# I2C0_1.0 register map
Vendor: Texas Instruments
Registers are 32-bit, read-write, no defined reset value unless marked. A register's access mark holds for its fields unless they carry their own. Offsets are as the file gives them; [hi:lo] are bit positions; lines under a group give offsets from that group; {n}, {i} and the like mark numbered series; 'fields as' and 'values as' point back to an identical list.

## I2C0 (part 2 of 2)
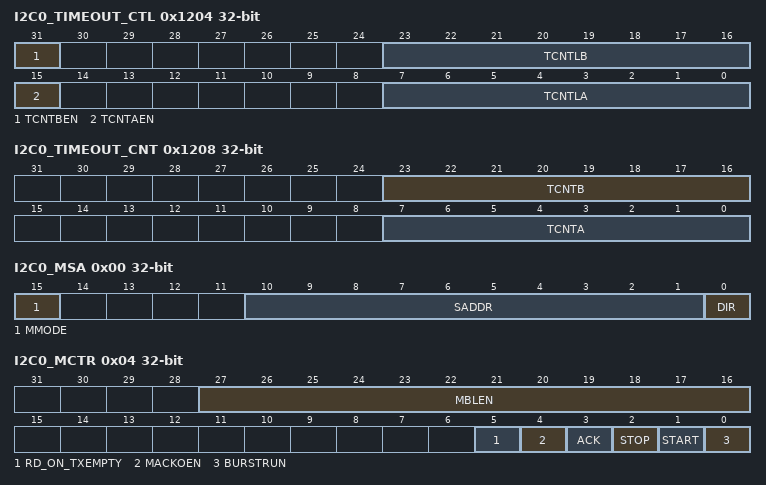
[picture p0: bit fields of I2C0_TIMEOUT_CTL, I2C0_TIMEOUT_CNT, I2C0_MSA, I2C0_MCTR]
0x1204 I2C0_TIMEOUT_CTL — I2C Timeout Count Control Register
  [31] TCNTBEN — Timeout Counter B Enable
    0=DISABLE (Disable Timeout Counter B); 1=ENABLE (Enable Timeout Counter B)
  [23:16] TCNTLB — Timeout Count B Load: Counter B is used for SCL High Detection. This field contains the upper 8 bits of a 12-bit pre-load value for the Timeout B count. NOTE: The value of CNTLB must be greater than 1h. Each count is equal to 1* clock period. For example, with 10MHz functional clock one timeout period will be equal to1*100ns.
    0=MINIMUM (Smallest possible value); 255=MAXIMUM (Highest possible value)
  [15] TCNTAEN — Timeout Counter A Enable
    values as TCNTBEN
  [7:0] TCNTLA — Timeout counter A load value Counter A is used for SCL low detection. This field contains the upper 8 bits of a 12-bit pre-load value for the Timeout A count. NOTE: The value of CNTLA must be greater than 1h. Each count is equal to 520 times the timeout period of functional clock. For example, with 8MHz functional clock and a 100KHz operating I2C clock, one timeout period will be equal to (1 / 8MHz) * 520 or 65 us.
    0=MINIMUM (Smallest Value); 255=MAXIMUM (Highest possible value)
0x1208 I2C0_TIMEOUT_CNT access per field — I2C Timeout Count Register
  [23:16] TCNTB rw — Timeout Count B Current Count: This field contains the upper 8 bits of a 12-bit current counter for timeout counter B
    values as I2C0_TIMEOUT_CTL.TCNTLA
  [7:0] TCNTA ro — Timeout Count A Current Count: This field contains the upper 8 bits of a 12-bit current counter for timeout counter A
    values as I2C0_TIMEOUT_CTL.TCNTLA
0x1210 I2C0_MASTER group
  0x00 I2C0_MSA — I2C Master Slave Address Register
    [15] MMODE — This bit selects the adressing mode to be used in master mode When 0, 7-bit addressing is used. When 1, 10-bit addressing is used.
      0=MODE7 (7-bit addressing mode); 1=MODE10 (10-bit addressing mode)
    [10:1] SADDR — I2C Slave Address This field specifies bits A9 through A0 of the slave address. In 7-bit addressing mode as selected by MSA.MODE bit, the top 3 bits are don't care
      0=MINIMUM (Smallest value); 0x3FF=MAXIMUM (Highest possible value)
    [0] DIR — Receive/Send The DIR bit specifies if the next master operation is a Receive (High) or Transmit (Low). 0h = Transmit 1h = Receive
      0=TRANSMIT (The master is in transmit mode.); 1=RECEIVE (The master is in receive mode.)
  0x04 I2C0_MCTR — I2C Master Control Register
    [27:16] MBLEN — I2C transaction length This field contains the programmed length of bytes of the Transaction.
      0=MINIMUM (Smallest value); 0xFFF=MAXIMUM (Highest possible value)
    [5] RD_ON_TXEMPTY — Read on TX Empty
      0=DISABLE (No special behavior); 1=ENABLE (When 1 the master will transmit all bytes from the TX FIFO before continuing with the programmed Burst Run Read. If the DIR is not set to Read in the MSA then this bit is ignored. The Start must be set in the MCTR for proper I2C protocol. The master will first send the Start Condition, I2C Address with R/W bit set to write, before sending the bytes in the TX FIFO. When the TX FIFO is empty, the I2C transaction will continue as programmed in MTCR and MSA without sending a Stop Condition. This is intended to be used to perform simple I2C command based reads transition that will complete after initiating them without having to get an interrupt to turn the bus around.)
    [4] MACKOEN — Master ACK overrride Enable
      0=DISABLE (No special behavior); 1=ENABLE (When 1 and the master is receiving data and the number of bytes indicated in MBLEN have been received, the state machine will generate an rxdone interrupt and wait at the start of the ACK for FW to indicate if an ACK or NACK should be sent. The ACK or NACK is selected by writing the MCTR register and setting ACK accordingly. The other fields in this register can also be written at this time to continue on with the transaction. If a NACK is sent the state machine will automatically send a Stop.)
    [3] ACK — Data Acknowledge Enable. Software needs to configure this bit to send the ACK or NACK. See field decoding in Table: MCTR Field decoding.
      0=DISABLE (The last received data byte of a transaction is not acknowledged automatically by the master.); 1=ENABLE (The last received data byte of a transaction is acknowledged automatically by the master.)
    [2] STOP — Generate STOP
      0=DISABLE (The controller does not generate the STOP condition.); 1=ENABLE (The controller generates the STOP condition. See field decoding in Table: MCTR Field decoding.)
    [1] START — Generate START
      0=DISABLE (The controller does not generate the START condition.); 1=ENABLE (The controller generates the START or repeated START condition. See field decoding in Table: MCTR Field decoding.)
    [0] BURSTRUN — I2C Master Enable and start transaction
      0=DISABLE (In standard mode, this encoding means the master is unable to transmit or receive data.); 1=ENABLE (The master is able to transmit or receive data. See field decoding in Table: MCTR Field decoding.)
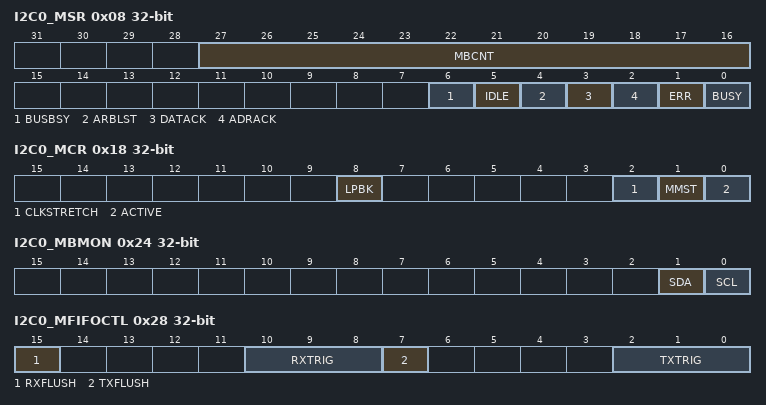
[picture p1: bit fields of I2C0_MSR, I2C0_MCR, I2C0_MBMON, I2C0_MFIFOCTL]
  0x08 I2C0_MSR ro — I2C Master Status Register
    [27:16] MBCNT — I2C Master Transaction Count This field contains the current count-down value of the transaction.
      values as I2C0_MASTER.I2C0_MCTR.MBLEN
    [6] BUSBSY — I2C Bus is Busy Master State Machine will wait until this bit is cleared before starting a transaction. When first enabling the Master in multi master environments, FW should wait for one I2C clock period after setting ACTIVE high before writing to the MTCR register to start the transaction so that if SCL goes low it will trigger the BUSBSY.
      0=CLEARED (The I2C bus is idle.); 1=SET ('This Status bit is set on a START or when SCL goes low. It is cleared on a STOP, or when a SCL high bus busy timeout occurs and SCL and SDA are both high. This status is cleared when the ACTIVE bit is low. Note that the Master State Machine will wait until this bit is cleared before starting an I2C transaction. When first enabling the Master in multi master environments, FW should wait for one I2C clock period after setting ACTIVE high before writing to the MTCR register to start the transaction so that if SCL goes low it will trigger the BUSBSY.)
    [5] IDLE — I2C Idle
      0=CLEARED (The I2C controller is not idle.); 1=SET (The I2C controller is idle.)
    [4] ARBLST — Arbitration Lost
      0=CLEARED (The I2C controller won arbitration.); 1=SET (The I2C controller lost arbitration.)
    [3] DATACK — Acknowledge Data
      0=CLEARED (The transmitted data was acknowledged); 1=SET (The transmitted data was not acknowledged.)
    [2] ADRACK — Acknowledge Address
      0=CLEARED (The transmitted address was acknowledged); 1=SET (The transmitted address was not acknowledged.)
    [1] ERR — Error The error can be from the slave address not being acknowledged or the transmit data not being acknowledged.
      0=CLEARED (No error was detected on the last operation.); 1=SET (An error occurred on the last operation.)
    [0] BUSY — I2C Master FSM Busy The BUSY bit is set during an ongoing transaction, so is set during the transmit/receive of the amount of data set in MBLEN including START, RESTART, Address and STOP signal generation when required for the current transaction.
      0=CLEARED (The controller is idle.); 1=SET (The controller is busy.)
  0x0C I2C0_MRXDATA ro — I2C Master RXData
    [7:0] VALUE — Received Data. This field contains the last received data.
      0=MINIMUM (Smallest value); 255=MAXIMUM (Highest possible value)
  0x10 I2C0_MTXDATA — I2C Master TXData
    [7:0] VALUE — Transmit Data This byte contains the data to be transferred during the next transaction.
      values as I2C0_MASTER.I2C0_MRXDATA.VALUE
  0x14 I2C0_MTPR — I2C Master Timer Period
    [6:0] TPR — Timer Period This field is used in the equation to configure SCL_PERIOD : SCL_PERIOD = (1 + TPR ) * (SCL_LP + SCL_HP ) * INT_CLK_PRD where: SCL_PRD is the SCL line period (I2C clock). TPR is the Timer Period register value (range of 1 to 127). SCL_LP is the SCL Low period (fixed at 6). SCL_HP is the SCL High period (fixed at 4). CLK_PRD is the functional clock period in ns.
      0=MINIMUM (Smallest value); 127=MAXIMUM (Highest possible value)
  0x18 I2C0_MCR — I2C Master Configuration
    [8] LPBK — I2C Loopback
      0=DISABLE (Normal operation.); 1=ENABLE (The controller in a test mode loopback configuration.)
    [2] CLKSTRETCH — Clock Stretching. This bit controls the support for clock stretching of the I2C bus.
      0=DISABLE (Disables the clock stretching detection. This can be disabled if no slave on the bus does support clock streching, so that the maximum speed on the bus can be reached.); 1=ENABLE (Enables the clock stretching detection. Enabling the clock strechting ensures compliance to the I2C standard but could limit the speed due the clock stretching.)
    [1] MMST — Multimaster mode. In Multimaster mode the SCL high time counts once the SCL line has been detected high. If this is not enabled the high time counts as soon as the SCL line has been set high by the I2C controller.
      0=DISABLE (Disable Multimaster mode.); 1=ENABLE (Enable Multimaster mode.)
    [0] ACTIVE — Device Active After this bit has been set, it should not be set again unless it has been cleared by writing a 0 or by a reset, otherwise transfer failures may occur.
      0=DISABLE (Disables the I2C master operation.); 1=ENABLE (Enables the I2C master operation.)
  0x24 I2C0_MBMON ro — I2C Master Bus Monitor
    [1] SDA — I2C SDA Status
      0=CLEARED (The I2CSDA signal is low.); 1=SET (The I2CSDA signal is high. Note: During and right after reset, the SDA pin is in GPIO input mode without the internal pull enabled. For proper I2C operation, the user should have the external pull-up resistor in place before starting any I2C operations.)
    [0] SCL — I2C SCL Status
      0=CLEARED (The I2CSCL signal is low.); 1=SET (The I2CSCL signal is high. Note: During and right after reset, the SCL pin is in GPIO input mode without the internal pull enabled. For proper I2C operation, the user should have the external pull-up resistor in place before starting any I2C operations.)
  0x28 I2C0_MFIFOCTL — I2C Master FIFO Control
    [15] RXFLUSH — RX FIFO Flush Setting this bit will Flush the RX FIFO. Before reseting this bit to stop Flush the RXFIFOCNT should be checked to be 0 and indicating that the Flush has completed.
      0=NOFLUSH (Do not Flush FIFO); 1=FLUSH (Flush FIFO)
    [10:8] RXTRIG — RX FIFO Trigger Indicates at what fill level in the RX FIFO a trigger will be generated. Note: Programming RXTRIG to 0x0 has no effect since no data is present to transfer out of RX FIFO.
      {v}=LEVEL_{v+1} (Trigger when RX FIFO contains >= {v+1} byte) (v=4..7)
    [7] TXFLUSH — TX FIFO Flush Setting this bit will Flush the TX FIFO. Before reseting this bit to stop Flush the TXFIFOCNT should be checked to be 8 and indicating that the Flush has completed.
      0=NOFLUSH (Do not Flush FIFO); 1=FLUSH (Flush FIFO)
    [2:0] TXTRIG — TX FIFO Trigger Indicates at what fill level in the TX FIFO a trigger will be generated.
      {v}=LEVEL_{v} (Trigger when TX FIFO contains {v} byte) (v=4..7)
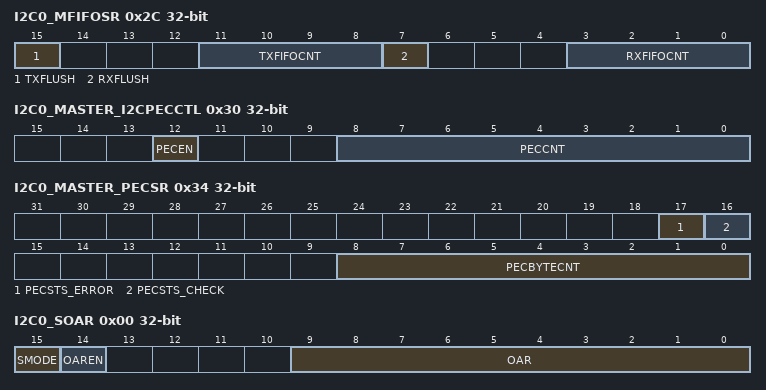
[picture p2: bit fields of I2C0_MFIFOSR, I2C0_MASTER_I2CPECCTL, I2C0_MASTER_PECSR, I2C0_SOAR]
  0x2C I2C0_MFIFOSR access per field — I2C Master FIFO Status Register
    [15] TXFLUSH rw — TX FIFO Flush When this bit is set a Flush operation for the TX FIFO is active. Clear the TXFLUSH bit in the control register to stop.
      0=INACTIVE (FIFO Flush not active); 1=ACTIVE (FIFO Flush active)
    [11:8] TXFIFOCNT ro — Number of Bytes which could be put into the TX FIFO
      0=MINIMUM (Smallest value); 8=MAXIMUM (Highest possible value)
    [7] RXFLUSH rw — RX FIFO Flush When this bit is set a Flush operation for the RX FIFO is active. Clear the RXFLUSH bit in the control register to stop.
      values as TXFLUSH
    [3:0] RXFIFOCNT ro — Number of Bytes which could be read from the RX FIFO
      values as TXFIFOCNT
  0x30 I2C0_MASTER_I2CPECCTL — I2C master PEC control register
    [12] PECEN — PEC Enable This bit enables the SMB Packet Error Checking (PEC). When enabled the PEC is calculated on all bits accept the Start, Stop, Ack and Nack. The PEC LSFR and the Byte Counter is set to 0 when the State Machine is in the IDLE state, which occur following a Stop or when a timeout occurs. The Counter is also set to 0 after the PEC byte is sent or received. Note that the NACK is automatically send following a PEC byte that results in a PEC error. The PEC Polynomial is x^8 + x^2 + x^1 + 1.
      0=DISABLE (PEC is disabled in master mode); 1=ENABLE (PEC is enabled in master mode)
    [8:0] PECCNT — PEC Count When this field is non zero, the number of I2C bytes are counted (Note that although the PEC is calculated on the I2C address it is not counted at a byte). When the byte count = PECCNT and the state machine is transmitting, the contents of the LSFR is loaded into the shift register instead of the byte received from the Tx FIFO. When the state machine is receiving, after the last bit of this byte is received the LSFR is checked and if it is non-zero, a PEC RX Error interrupt is generated. The I2C packet must be padded to include the PEC byte for both transmit and receive. In transmit mode the FIFO must be loaded with a dummy PEC byte. In receive mode the PEC byte will be passed to the Rx FIFO. In the normal Master use case, FW would set PECEN=1 and PECCNT=SMB packet length (Not including Slave Address byte, but including the PEC byte). FW would then configure DMA to allow the packet to complete unassisted and write MCTR to initiate the transaction. Note that when the byte count = PEC CNT, the byte count is reset to 0 and multiple PEC calculation can automatically occur within a single I2C transaction. Note that any write to the MASTER_I2CPECCTL Register will clear the current PEC Byte Count in the Master State Machine.
      0=MINIMUM (Minimum Value); 0x1FF=MAXIMUM (Maximum Value)
  0x34 I2C0_MASTER_PECSR — I2C master PEC status register
    [17] PECSTS_ERROR — This status bit indicates if a PEC check error occurred in the transaction that occurred before the last Stop. Latched on Stop.
      0=CLEARED (Indicates PEC check error did not occurr in the transaction that occurred before the last Stop); 1=SET (Indicates if a PEC check error occurred in the transaction that occurred before the last Stop)
    [16] PECSTS_CHECK — This status bit indicates if the PEC was checked in the transaction that occurred before the last Stop. Latched on Stop.
      0=CLEARED (Indicates PEC was not checked in the transaction that occurred before the last Stop); 1=SET (Indicates if the PEC was checked in the transaction that occurred before the last Stop)
    [8:0] PECBYTECNT — PEC Byte Count This is the current PEC Byte Count of the Master State Machine.
      0=MINIMUM (Minimum Value); 0x1FF=MAXIMUM (Maximum Value)
0x1250 I2C0_SLAVE group
  0x00 I2C0_SOAR — I2C Slave Own Address
    [15] SMODE — This bit selects the adressing mode to be used in slave mode. When 0, 7-bit addressing is used. When 1, 10-bit addressing is used.
      0=MODE7 (Enable 7-bit addressing); 1=MODE10 (Enable 10-bit addressing)
    [14] OAREN — I2C Slave Own Address Enable
      0=DISABLE (Disable OAR address); 1=ENABLE (Enable OAR address)
    [9:0] OAR — I2C Slave Own Address: This field specifies bits A9 through A0 of the slave address. In 7-bit addressing mode as selected by I2CSOAR.MODE bit, the top 3 bits are don't care
      values as I2C0_MASTER.I2C0_MSA.SADDR
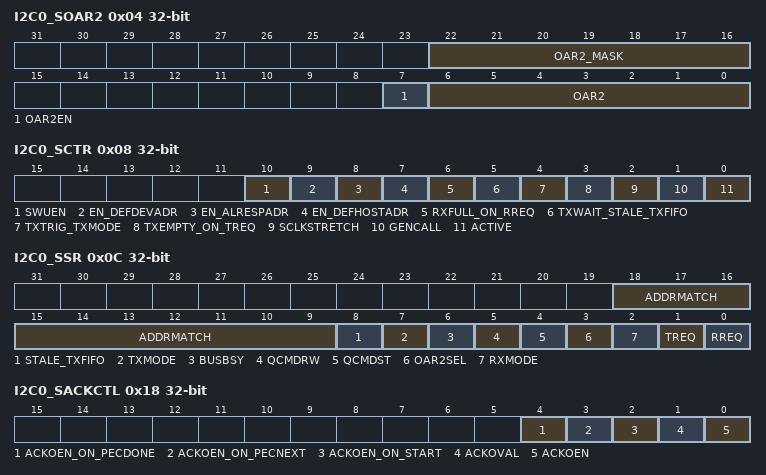
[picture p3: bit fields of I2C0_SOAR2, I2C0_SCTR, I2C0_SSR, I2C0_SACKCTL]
  0x04 I2C0_SOAR2 — I2C Slave Own Address 2
    [22:16] OAR2_MASK — I2C Slave Own Address 2 Mask: This field specifies bits A6 through A0 of the slave address. The bits with value 1 in SOAR2.OAR2_MASK field will make the corresponding incoming address bits to match by default regardless of the value inside SOAR2.OAR2 i.e. corresponding SOAR2.OAR2 bit is a dont care.
      0=MINIMUM (Minimum Value); 127=MAXIMUM (Maximum Value)
    [7] OAR2EN — I2C Slave Own Address 2 Enable
      0=DISABLE (The alternate address is disabled.); 1=ENABLE (Enables the use of the alternate address in the OAR2 field.)
    [6:0] OAR2 — I2C Slave Own Address 2 This field specifies the alternate OAR2 address.
      values as I2C0_MASTER.I2C0_MTPR.TPR
  0x08 I2C0_SCTR — I2C Slave Control Register
    [10] SWUEN — Slave Wakeup Enable
      0=DISABLE (When 0, the slave is not allowed to clock stretch on START detection); 1=ENABLE (When 1, the slave is allowed to clock stretch on START detection and wait for faster clock to be abvailable. This allows clean wake up support for I2C in low power mode use cases)
    [9] EN_DEFDEVADR — Enable Deault device address
      0=DISABLE (When this bit is 0, the default device address is not matched. NOTE: it may still be matched if programmed inside SOAR/SOAR2.); 1=ENABLE (When this bit is 1, default device address of 7h110_0001 is always matched by the slave address match logic.)
    [8] EN_ALRESPADR — Enable Alert Response Address
      0=DISABLE (When this bit is 0, the alert response address is not matched. NOTE: it may still be matched if programmed inside SOAR/SOAR2); 1=ENABLE (When this bit is 1, alert response address of 7h000_1100 is always matched by the slave address match logic.)
    [7] EN_DEFHOSTADR — Enable Default Host Address
      0=DISABLE (When this bit is 0, the default host address is not matched NOTE: it may still be matched if programmed inside SOAR/SOAR2); 1=ENABLE (When this bit is 1, default host address of 7h000_1000 is always matched by the slave address match logic.)
    [6] RXFULL_ON_RREQ — Rx full interrupt generated on RREQ condition as indicated in SSR
      0=DISABLE (When 0, RIS:SRXFULL will be set when only the Slave RX FIFO is full. This allows the SRXFULL interrupt to be used to indicate that the I2C bus is being clock stretched and that the FW must either read the RX FIFO or ACK/NACK the current Rx byte.); 1=ENABLE (When 1, RIS:SRXFULL will be set when the Slave State Machine is in the RX_WAIT or RX_ACK_WAIT states which occurs when the I2C transaction is clock stretched because the RX FIFO is full or the ACKOEN has been set and the state machine is waiting for FW to ACK/NACK the current byte.)
    [5] TXWAIT_STALE_TXFIFO — Tx transfer waits when stale data in Tx FIFO. This prevents stale bytes left in the TX FIFO from automatically being sent on the next I2C packet. Note: this should be used with TXEMPTY_ON_TREQ set to prevent the Slave State Machine from waiting for TX FIFO data without an interrupt notification when the FIFO data is stale.
      0=DISABLE (When 0, the TX FIFO empty signal to the Slave State Machine indicates that the TX FIFO is empty.); 1=ENABLE (When 1, the TX FIFO empty signal to the Slave State Machine will indicate that the TX FIFO is empty or that the TX FIFO data is stale. The TX FIFO data is determined to be stale when there is data in the TX FIFO when the Slave State Machine leaves the TXMODE as defined in the SSR register. This can occur is a Stop or timeout occur when there are bytes left in the TX FIFO.)
    [4] TXTRIG_TXMODE — Tx Trigger when slave FSM is in Tx Mode
      0=DISABLE (No special behavior); 1=ENABLE (When 1, RIS:TXFIFOTRG will be set when the Slave TX FIFO has reached the trigger level AND the Slave State Machine is in the TXMODE as defined in the SSR register. When cleared RIS:TXFIFOTRG will be set when the Slave TX FIFO is at or above the trigger level. This setting can be used to hold off the TX DMA until a transaction starts. This allows the DMA to be configured when the I2C is idle but have it wait till the transaction starts to load the Slave TX FIFO, so it can load from a memory buffer that might be changing over time.)
    [3] TXEMPTY_ON_TREQ — Tx Empty Interrupt on TREQ
      0=DISABLE (When 0, RIS:STXEMPTY will be set when only the Slave TX FIFO is empty. This allows the STXEMPTY interrupt to be used to indicate that the I2C bus is being clock stretched and that Slave TX data is required.); 1=ENABLE (When 1, RIS:STXEMPTY will be set when the Slave State Machine is in the TX_WAIT state which occurs when the TX FIFO is empty AND the I2C transaction is clock stretched waiting for the FIFO to receive data.)
    [2] SCLKSTRETCH — Slave Clock Stretch Enable
      0=DISABLE (Slave clock stretching is disabled); 1=ENABLE (Slave clock stretching is enabled)
    [1] GENCALL — General call response enable. This bit is only available in UCBxI2COA0. Modify only when UCSWRST = 1. 0b = Do not respond to a general call 1b = Respond to a general call
      0=DISABLE (Do not respond to a general call); 1=ENABLE (Respond to a general call)
    [0] ACTIVE — Device Active. Setting this bit enables the slave functionality.
      0=DISABLE (Disables the I2C slave operation.); 1=ENABLE (Enables the I2C slave operation.)
  0x0C I2C0_SSR access per field — I2C Slave Status Register
    [18:9] ADDRMATCH rw — Indicates the address for which slave address match happened
      0=MINIMUM (Minimum Value); 0x3FF=MAXIMUM (Maximum Value)
    [8] STALE_TXFIFO rw
      0=CLEARED (Tx FIFO is not stale); 1=SET (The TX FIFO is stale. This occurs when the TX FIFO was not emptied during the previous I2C transaction.)
    [7] TXMODE rw — Slave FSM is in TX MODE
      0=CLEARED (The Slave State Machine is not in TX_DATA, TX_WAIT, TX_ACK or ADDR_ACK state with the bus direction set to read.); 1=SET (The Slave State Machine is in TX_DATA, TX_WAIT, TX_ACK or ADDR_ACK state with the bus direction set to read.)
    [6] BUSBSY rw — I2C bus is busy
      0=CLEARED (The I2C Bus is not busy); 1=SET (The I2C Bus is busy. This is cleared on a timeout.)
    [5] QCMDRW ro — Quick Command Read / Write This bit only has meaning when the QCMDST bit is set. Value Description: 0: Quick command was a write 1: Quick command was a read
      0=CLEARED (Quick command was a write); 1=SET (Quick command was a read)
    [4] QCMDST ro — Quick Command Status Value Description: 0: The last transaction was a normal transaction or a transaction has not occurred. 1: The last transaction was a Quick Command transaction
      0=CLEARED (The last transaction was a normal transaction or a transaction has not occurred.); 1=SET (The last transaction was a Quick Command transaction.)
    [3] OAR2SEL ro — OAR2 Address Matched This bit gets reevaluated after every address comparison.
      0=CLEARED (Either the OAR2 address is not matched or the match is in legacy mode.); 1=SET (OAR2 address matched and ACKed by the slave.)
    [2] RXMODE rw — Slave FSM is in Rx MODE
      0=CLEARED (The Slave State Machine is not in the RX_DATA, RX_ACK, RX_WAIT, RX_ACK_WAIT or ADDR_ACK state with the bus direction set to write.); 1=SET (The Slave State Machine is in the RX_DATA, RX_ACK, RX_WAIT, RX_ACK_WAIT or ADDR_ACK state with the bus direction set to write.)
    [1] TREQ ro — Transmit Request
      0=CLEARED (No outstanding transmit request.); 1=SET (The I2C controller has been addressed as a slave transmitter and is using clock stretching to delay the master until data has been written to the STXDATA FIFO (Slave TX FIFO is empty).)
    [0] RREQ ro — Receive Request
      0=CLEARED (No outstanding receive data.); 1=SET (The I2C controller has outstanding receive data from the I2C master and is using clock stretching to delay the master until the data has been read from the SRXDATA FIFO (Slave RX FIFO is full).)
  0x10 I2C0_SRXDATA ro — I2C Slave RXData
    fields as I2C0_MASTER.I2C0_MRXDATA
  0x14 I2C0_STXDATA — I2C Slave TXData
    fields as I2C0_MASTER.I2C0_MTXDATA
  0x18 I2C0_SACKCTL — I2C Slave ACK Control
    [4] ACKOEN_ON_PECDONE — When set this bit will automatically turn on the Slave ACKOEN field following the ACK/NACK of the received PEC byte.
      0=DISABLE (No special behavior); 1=ENABLE (When set this bit will automatically turn on the Slave ACKOEN field following the ACK/NACK of the received PEC byte.)
    [3] ACKOEN_ON_PECNEXT — When set this bit will automatically turn on the Slave ACKOEN field following the ACK/NACK of the byte received just prior to the PEC byte. Note that when ACKOEN is set the PEC byte will not automatically be ACKed/NACKed by the State Machine and FW must perform this function by writing SLAVE_SACKCTL.
      0=DISABLE (No special behavior); 1=ENABLE (When set this bit will automatically turn on the Slave ACKOEN field following the ACK/NACK of the byte received just prior to the PEC byte. Note that when ACKOEN is set the PEC byte will not automatically be ACKed/NACKed by the State Machine and FW must perform this function by writing SLAVE_SACKCTL.)
    [2] ACKOEN_ON_START — When set this bit will automatically turn on the Slave ACKOEN field following a Start Condition.
      0=DISABLE (No special behavior); 1=ENABLE (When set this bit will automatically turn on the Slave ACKOEN field following a Start Condition.)
    [1] ACKOVAL — I2C Slave ACK Override Value Note: for General Call this bit will be ignored if set to NACK and slave continues to receive data.
      0=DISABLE (An ACK is sent indicating valid data or command.); 1=ENABLE (A NACK is sent indicating invalid data or command.)
    [0] ACKOEN — I2C Slave ACK Override Enable
      0=DISABLE (A response in not provided.); 1=ENABLE (An ACK or NACK is sent according to the value written to the ACKOVAL bit.)
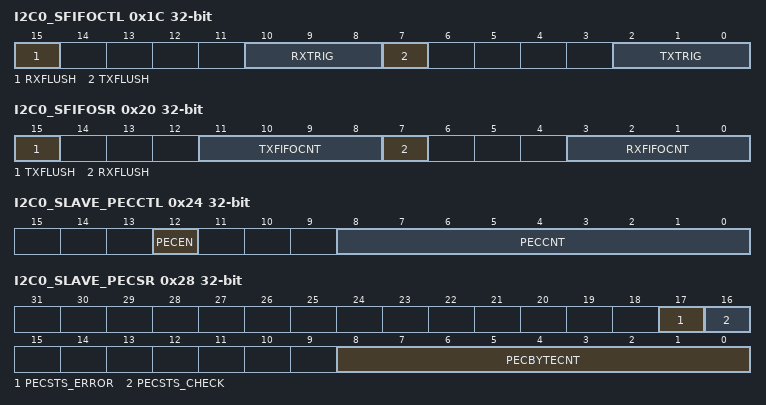
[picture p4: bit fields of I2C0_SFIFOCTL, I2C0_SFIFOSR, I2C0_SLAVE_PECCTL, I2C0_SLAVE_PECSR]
  0x1C I2C0_SFIFOCTL — I2C Slave FIFO Control
    fields as I2C0_MASTER.I2C0_MFIFOCTL
  0x20 I2C0_SFIFOSR access per field — I2C Slave FIFO Status Register
    [15] TXFLUSH rw — TX FIFO Flush When this bit is set a Flush operation for the TX FIFO is active. Clear the TXFLUSH bit in the control register to stop.
      values as I2C0_MASTER.I2C0_MFIFOSR.TXFLUSH
    [11:8] TXFIFOCNT ro — Number of Bytes which could be put into the TX FIFO
      values as I2C0_MASTER.I2C0_MFIFOSR.TXFIFOCNT
    [7] RXFLUSH rw — RX FIFO Flush When this bit is set a Flush operation for the RX FIFO is active. Clear the RXFLUSH bit in the control register to stop.
      0=INACTIVE (FIFOFlush not active); 1=ACTIVE (FIFO Flush active)
    [3:0] RXFIFOCNT ro — Number of Bytes which could be read from the RX FIFO
      values as I2C0_MASTER.I2C0_MFIFOSR.TXFIFOCNT
  0x24 I2C0_SLAVE_PECCTL — I2C Slave PEC control register
    [12] PECEN — PEC Enable This bit enables the SMB Packet Error Checking (PEC). When enabled the PEC is calculated on all bits accept the Start, Stop, Ack and Nack. The PEC LSFR and the Byte Counter is set to 0 when the State Machine is in the IDLE state, which occur following a Stop or when a timeout occurs. The Counter is also set to 0 after the PEC byte is sent or received. Note that the NACK is automatically send following a PEC byte that results in a PEC error. The PEC Polynomial is x^8 + x^2 + x^1 + 1.
      0=DISABLE (PEC transmission and check is disabled); 1=ENABLE (PEC transmission and check is enabled)
    [8:0] PECCNT — When this field is non zero, the number of I2C data bytes are counted. When the byte count = PECCNT and the state machine is transmitting, the contents of the LSFR is loaded into the shift register instead of the byte received from the Tx FIFO. When the state machine is receiving, after the last bit of this byte is received the LSFR is checked and if it is non-zero, a PEC RX Error interrupt is generated. The I2C packet must be padded to include the PEC byte for both transmit and receive. In transmit mode the FIFO must be loaded with a dummy PEC byte. In receive mode the PEC byte will be passed to the Rx FIFO. In the normal Slave use case, FW would set PECEN=1 and PECCNT=0 and use the ACKOEN until the remaining SMB packet length is known. FW would then set the PECCNT to the remaining packet length (Including PEC bye). FW would then configure DMA to allow the packet to complete unassisted and exit NoAck mode. Note that when the byte count = PEC CNT, the byte count is reset to 0 and multiple PEC calculation can automatically occur within a single I2C transaction
      0=MINIMUM (Minimum Value); 0x1FF=MAXIMUM (Maximum Value)
  0x28 I2C0_SLAVE_PECSR — I2C slave PEC status register
    [17] PECSTS_ERROR — This status bit indicates if a PEC check error occurred in the transaction that occurred before the last Stop. Latched on Stop.
      0=CLEARED (Indicates PEC check error did not occurr in the transaction that occurred before the last Stop); 1=SET (Indicates PEC check error occurred in the transaction that occurred before the last Stop)
    [16] PECSTS_CHECK — This status bit indicates if the PEC was checked in the transaction that occurred before the last Stop. Latched on Stop.
      0=CLEARED (Indicates PEC was not checked in the transaction that occurred before the last Stop); 1=SET (Indicates PEC was checked in the transaction that occurred before the last Stop)
    [8:0] PECBYTECNT — This is the current PEC Byte Count of the Slave State Machine.
      0=MINIMUM (Minimum Value); 0x1FF=MAXIMUM (Maximum Value)
